# liliumFP1_sysctrl register map
Vendor: Nordic Semiconductor; Series: liliumFP1; File version: 1
Registers are 32-bit, read-write, reset 0x0 unless marked. A register's access mark holds for its fields unless they carry their own. Offsets are from the block's base; [hi:lo] are bit positions; lines under a group give offsets from that group; {n}, {i} and the like mark numbered series.

## LRCCONF200_S — LRCCONF 0
Base 0xBF005000
Same registers: LRCCONF120_S 0x5F8CE000, LRCCONF130_S 0x5F93E000, LRCCONF210_S 0xBF012000
{0x0+4i} TASKS_REQCLKSRC[{i}] (i=0..7) wo — Description collection: Request the clock source for clock [n]
  [0] TASKS_REQCLKSRC — Request the clock source for clock [n]
    1=Trigger task
{0x20+4i} TASKS_STOPREQCLKSRC[{i}] (i=0..7) wo — Description collection: Stop requesting the clock source for clock [n]
  [0] TASKS_STOPREQCLKSRC — Stop requesting the clock source for clock [n]
    1=Trigger task
0x40 TASKS_CONSTLAT group — Peripheral tasks.
  0x00 ENABLE wo — Enable constant latency mode
    [0] ENABLE
      1=Trigger task
  0x04 DISABLE wo — Disable constant latency mode
    [0] DISABLE
      1=Trigger task
0x48 TASKS_SYSTEMOFF group — Peripheral tasks.
  0x00 NOTREADY wo — Not ready to go to System OFF
    [0] NOTREADY
      1=Trigger task
  0x04 READY wo — Ready to go to System OFF
    [0] READY
      1=Trigger task
{0x100+4i} EVENTS_CLKSRCSTARTED[{i}] (i=0..7) — Description collection: Clock source is started for clock [n]
  [0] EVENTS_CLKSRCSTARTED — Clock source is started for clock [n]
    0=NotGenerated (Event not generated); 1=Generated (Event generated)
{0x400+8i} CLKSTAT[{i}] (i=0..7) group — Unspecified
  0x00 RUN — Description cluster: Status indicating that TASKS_REQCLKSRC task has been triggered for clock [n].
    [0] STATUS ro — Clock start task triggered or not
      0=NotTriggered (Task not triggered); 1=Triggered (Task triggered)
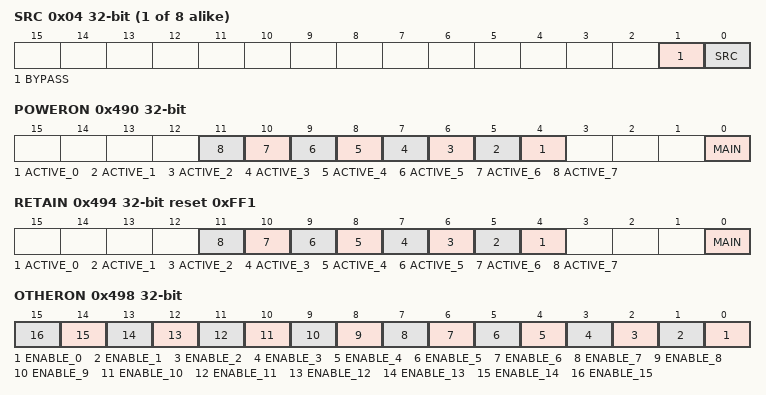
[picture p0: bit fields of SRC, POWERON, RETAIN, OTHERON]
  0x04 SRC — Description cluster: Status indicating clock source for clock [n]
    [1] BYPASS ro — Clock source bypass status
      0=Disable (Clock source bypass is disabled.); 1=Enable (Clock source bypass is enabled.)
    [0] SRC ro — Clock source status
      0=OpenLoop; 1=ClosedLoop
{0x440+8i} CLKCTRL[{i}] (i=0..7) group — Unspecified
  0x00 ALWAYSRUN — Description cluster: Force the clock [n] and tree running always
    [0] FORCE — Force the clock always running
      0=Automatic clock control enabled; 1=AlwaysRun (Clock always running)
  0x04 SRC — Description cluster: Select the clock source for clock [n]
    [1] BYPASS — Clock source bypass
      0=Disable the clock source bypass; 1=Enable the clock source bypass
    [0] SRC — Clock source
      0=OpenLoop; 1=ClosedLoop
0x480 CONSTLATSTAT ro — Status of constant latency
  [0] STATUS
    0=Disable (Constant latency disabled.); 1=Enable (Constant latency enabled.)
0x490 POWERON — Force power domain ON
  [all] fields
    0=Automatic power control enabled; 1=AlwaysOn (Keep the power domain ON even though there is no request)
  [n+4] ACTIVE_{n} (n=0..7) — Force the active power domain[{n}] ON
  [0] MAIN — Force the main power domain ON
0x494 RETAIN reset 0xFF1 — Retain power domain
  [all] fields
    0=Disable (Retain disabled); 1=Enable (Retain enabled)
  [n+4] ACTIVE_{n} (n=0..7) — Retain the active power domain[{n}]
  [0] MAIN ro — Retain the main power domain
0x498 OTHERON — Request other domain ON
  [all] fields
    0=Automatic power control enabled; 1=AlwaysOn (Request to keep the other power domain ON even though there is no request)
  [n] ENABLE_{n} (n=0..15) — Request power domain[{n}] ON
{0x500+4i} AX2XWAITSTATES[{i}] (i=0..15) reset 0x7 — Description collection: AX2X bridge waitstates for the domain [n], where n is the Domain ID.
  [2:0] WAITSTATES — Number of waitstates

## PCGCM200_S — PCGC Master 0
Base 0xBF006000
Same registers: PCGCM110_S 0x5F08F000, PCGCM120_S 0x5F8CF000, PCGCM121_S 0x5F8ED000, PCGCM130_S 0x5F93D000, PCGCM131_S 0x5F93F000, PCGCM132_S 0x5F94F000, PCGCM133_S 0x5F98F000, PCGCM134_S 0x5F99F000, PCGCM135_S 0x5F9AF000, PCGCM136_S 0x5F9BF000, PCGCM137_S 0x5F9CF000, PCGCM138_S 0x5F9DF000, PCGCM210_S 0xBF013000
{0xE0+4i} SETPWRCONTHRESHOLDBASE[{i}] (i=0..2) — Description collection: Set power consumption threshold base for power source / regulator n
  [3:0] SETPWRCONTHRESHOLDBASE
{0x100+4i} SETPOWERCONSUMPTIONBASE[{i}] (i=0..1) — Description collection: Set power consumption base for power/clock pair n
  [3:0] POWERREQUIREMENT
0xC00 UNLOCKBACKDOORS
  [15:0] UNLOCKBACKDOORS — Write: 0x00009375 to lock/unlock backdoors Read: 0x00000001 if backdoors is enabled Read: 0x00000000 if backdoors is disabled
0xC04 ENABLEPOWERREGFORCE
  [2:0] ENABLEPOWERREGFORCE
0xC08 POWERREGFORCE — Force reg
  [2:0] POWERREGFORCEREG
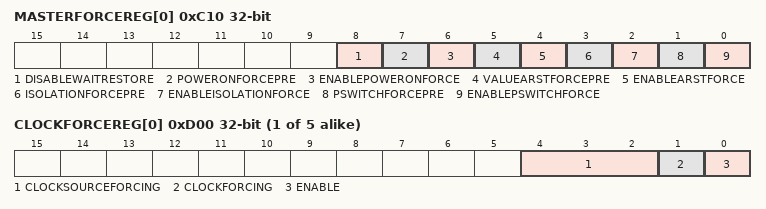
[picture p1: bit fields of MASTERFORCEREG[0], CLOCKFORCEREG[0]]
{0xC10+4i} MASTERFORCEREG[{i}] (i=0..0) — Description collection: Force reg
  [8] DISABLEWAITRESTORE — Turn off waiting for arst deactivation before retention restore
    1=Disable (Turn off waiting for arst deactivation before retention restore); 0=Enable (Wait for arst deactivation before retention restore)
  [7] POWERONFORCEPRE
  [6] ENABLEPOWERONFORCE
  [5] VALUEARSTFORCEPRE
  [4] ENABLEARSTFORCE
  [3] ISOLATIONFORCEPRE
  [2] ENABLEISOLATIONFORCE
  [1] PSWITCHFORCEPRE
  [0] ENABLEPSWITCHFORCE
{0xD00+4i} CLOCKFORCEREG[{i}] (i=0..4) — Description collection: Force clock n
  [4:2] CLOCKSOURCEFORCING
  [1] CLOCKFORCING
  [0] ENABLE — Enable clock forcing
